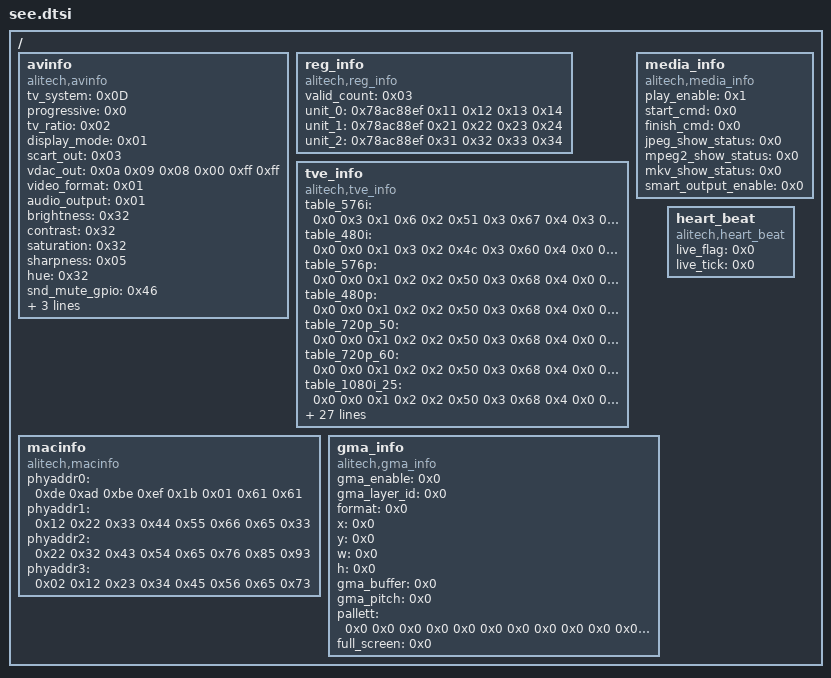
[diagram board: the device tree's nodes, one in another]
/*
 * ALi platform DTS
 * Copyright(C) 2014 ALi Corporation. All rights reserved.
 *
 * This program is free software; you can redistribute it and/or modify
 * it under the terms of the GNU General Public License version 2 as
 * published by the Free Software Foundation.
 *
 * This program is distributed in the hope that it will be useful,
 * but WITHOUT ANY WARRANTY; without even the implied warranty of
 * MERCHANTABILITY or FITNESS FOR A PARTICULAR PURPOSE.  See the
 * GNU General Public License for more details.
 */

/{
		#size-cells = <2>;
		avinfo{
			compatible="alitech,avinfo";
			/*eric.cai debug*/
			/* tv_system = /bits/ 8 <0x0D>; */
			tv_system = /bits/ 8 <0x0D>; 
			progressive = /bits/ 8 <0x0>;
			tv_ratio= /bits/ 8 <0x02>;
			display_mode = /bits/ 8 <0x01>;
			scart_out = /bits/ 8 <0x03>;
			vdac_out = /bits/ 8 <0x0a 0x09 0x08 0x00 0xff 0xff>;
			video_format = /bits/ 8 <0x01>;
			audio_output = /bits/ 8 <0x01>;
			brightness = /bits/ 8 <0x32>;
			contrast = /bits/ 8 <0x32>;
			saturation = /bits/ 8 <0x32>;
			sharpness = /bits/ 8 <0x05>;
			hue = /bits/ 8 <0x32>;
			snd_mute_gpio = /bits/ 8 <0x46>;
			snd_mute_polar = /bits/ 8 <0x0>;
			hdcp_disable = /bits/ 8 <0x01>;
			resv = /bits/ 8 <0x00 0x01 0x02 0x03 0x04 0x05 0x06>;
		};
		reg_info{
					compatible="alitech,reg_info";
					valid_count = <0x03>;
					unit_0 = <0x78ac88ef 0x11 0x12 0x13  0x14>; /* magic addr bits_offset bits_size bits_value */
					unit_1 = <0x78ac88ef 0x21 0x22 0x23  0x24>;
					unit_2 = <0x78ac88ef 0x31 0x32 0x33  0x34>;
		};

		tve_info{
		compatible="alitech,tve_info";
		table_576i = /* field_index  field_value */
								< 0x0 0x3    0x1 0x6   0x2 0x51   0x3 0x67   0x4 0x3   0x5 0x2   0x6 0x0    0x7 0x1   0x8 0x0    0x9  0x1 
									0xa 0x0    0xb 0x0   0xc 0x0    0xd 0x1    0xe 0x1   0xf 0x2   0x10 0x2   0x11 0x2  0x12 0x52  0x13 0x50
									0x14 0xb   0x15 0x0  0x16 0x7   0x17 0x3   0x18 0x0  0x19 0x0  0x1a  0x0  0x1b 0x47 0x1c 0x47  0x1d 0x47 
									0x1e 0x1   0x1f 0x1  0x20 0x0   0x21 0x0   0x22 0x0  0x23 0x12a 0x24 0x64 0x25 0xd0 0x26 0x205 0x27  0x198 
									0x28 0x1   0x29 0x1  0x2a 0x96  0x2b 0x6a  0x2c 0x55 0x2d 0x74  0x2e 0x0  0x2f 0x0  0x30 0x61e8 0x31 0x0 
									0x32 0x4   0x33 0x1  0x34 0x6   0x35 0xd   0x36 0x0  0x37 0x0   0x38 0x0  0x39 0x0  0x3a 0x0    0x3b 0x0 
									0x3c 0x0   0x3d 0x0  0x3e 0x0   0x3f 0x0   0x40 0x0  0x41 0x1   0x42 0x4  0x43 0x0  0x44 0x0    0x45 0x60 
									0x46 0x0   0x47 0x0  0x48 0x1f  0x49 0x2   0x4a 0x0  0x0  0x0   0x0  0x0  0x0 0x0   0x0  0x0    0x0  0x0 
									0x0  0x0   0x0  0x0  0x0  0x0   0x0  0x0   0x0  0x0  0x0  0x0   0x0  0x0  0x0 0x0   0x0  0x0    0x0  0x0 
									0x0  0x0   0x0  0x0  0x0  0x0   0x0  0x0   0x0  0x0  0x0  0x0   0x0  0x0  0x0 0x0   0x0  0x0    0x0  0x0 >;
		table_480i = /* field_index  field_value */
								< 0x0     0x0     0x1     0x3     0x2     0x4c    0x3     0x60    0x4     0x0     0x5     0x5     0x6   0x0     0x7     0x1     0x8     0x0     0x9     0x0 
0xa     0x0     0xb     0x0     0xc     0x1     0xd     0x1     0xe     0x1     0xf     0x3     0x10    0x1     0x11    0x1     0x12    0x4c    0x13    0x52 
0x14    0xb     0x15    0x0     0x16    0x7     0x17    0x3     0x18    0x0     0x19    0x0     0x1a    0x0     0x1b    0x47    0x1c    0x47    0x1d    0x47 
0x1e    0x1     0x1f    0x1     0x20    0x1     0x21    0x1     0x22    0xa8    0x23    0x12a   0x24    0x64    0x25    0xd0    0x26    0x205   0x27    0x198 
0x28    0x0     0x29    0x1     0x2a    0xd4    0x2b    0x0     0x2c    0x55    0x2d    0x74    0x2e    0x0     0x2f    0x0     0x30    0x3400  0x31    0x0 
0x32    0x4     0x33    0x1     0x34    0x6     0x35    0xd     0x36    0x0     0x37    0x0     0x38    0x0     0x39    0x0     0x3a    0x0     0x3b    0x0 
0x3c    0x0     0x3d    0x0     0x3e    0x0     0x3f    0x0     0x40    0x0     0x41    0x1     0x42    0x7     0x43    0x1     0x44    0x1     0x45    0x60 
0x46    0x0     0x47    0x0     0x48    0x1f    0x49    0x2     0x4a    0x0     0x0     0x0     0x0     0x0     0x0     0x0     0x0     0x0     0x0     0x0 
0x0     0x0     0x0     0x0     0x0     0x0     0x0     0x0     0x0     0x0     0x0     0x0     0x0     0x0     0x0     0x0     0x0     0x0     0x0     0x0 
0x0     0x0     0x0     0x0     0x0     0x0     0x0     0x0     0x0     0x0     0x0     0x0     0x0     0x0     0x0     0x0     0x0     0x0     0x0     0x0  >;
		table_576p = /* field_index  field_value */
								< 0x0     0x0     0x1     0x2     0x2     0x50    0x3     0x68    0x4     0x0     0x5     0x4     0x6     0x0     0x7     0x1     0x8     0x0     0x9     0x0 
0xa     0x0     0xb     0x0     0xc     0x0     0xd     0x1     0xe     0x1     0xf     0x1     0x10    0x1     0x11    0x1     0x12    0x52    0x13    0x52 
0x14    0xa     0x15    0x0     0x16    0x7     0x17    0x3     0x18    0x0     0x19    0x0     0x1a    0x0     0x1b    0x49    0x1c    0x49    0x1d    0x49 
0x1e    0x1     0x1f    0x1     0x20    0x0     0x21    0x0     0x22    0x0     0x23    0x12a   0x24    0x64    0x25    0xd0    0x26    0x205   0x27    0x198 
0x28    0x0     0x29    0x0     0x2a    0xd4    0x2b    0x0     0x2c    0x0     0x2d    0x0     0x2e    0x0     0x2f    0x0     0x30    0x0     0x31    0x0 
0x32    0x4     0x33    0x1     0x34    0x6     0x35    0xd     0x36    0x0     0x37    0x0     0x38    0x0     0x39    0x0     0x3a    0x0     0x3b    0x0 
0x3c    0x0     0x3d    0x0     0x3e    0x0     0x3f    0x0     0x40    0x0     0x41    0x1     0x42    0xe     0x43    0x0     0x44    0x0     0x45    0x60 
0x46    0x0     0x47    0x0     0x48    0x1f    0x49    0x2     0x4a    0x0     0x0     0x0     0x0     0x0     0x0     0x0     0x0     0x0     0x0     0x0 
0x0     0x0     0x0     0x0     0x0     0x0     0x0     0x0     0x0     0x0     0x0     0x0     0x0     0x0     0x0     0x0     0x0     0x0     0x0     0x0 
0x0     0x0     0x0     0x0     0x0     0x0     0x0     0x0     0x0     0x0     0x0     0x0     0x0     0x0     0x0     0x0     0x0     0x0     0x0     0x0  >;
		table_480p = /* field_index  field_value */
								< 0x0     0x0     0x1     0x2     0x2     0x50    0x3     0x68    0x4     0x0     0x5     0x4     0x6     0x0     0x7     0x1     0x8     0x0     0x9     0x0 
0xa     0x0     0xb     0x0     0xc     0x0     0xd     0x1     0xe     0x1     0xf     0x1     0x10    0x1     0x11    0x1     0x12    0x52    0x13    0x52 
0x14    0xa     0x15    0x0     0x16    0x7     0x17    0x3     0x18    0x0     0x19    0x0     0x1a    0x0     0x1b    0x49    0x1c    0x49    0x1d    0x49 
0x1e    0x1     0x1f    0x1     0x20    0x0     0x21    0x0     0x22    0x0     0x23    0x12a   0x24    0x64    0x25    0xd0    0x26    0x205   0x27    0x198 
0x28    0x0     0x29    0x0     0x2a    0xd4    0x2b    0x0     0x2c    0x0     0x2d    0x0     0x2e    0x0     0x2f    0x0     0x30    0x0     0x31    0x0 
0x32    0x4     0x33    0x1     0x34    0x6     0x35    0xd     0x36    0x0     0x37    0x0     0x38    0x0     0x39    0x0     0x3a    0x0     0x3b    0x0 
0x3c    0x0     0x3d    0x0     0x3e    0x0     0x3f    0x0     0x40    0x0     0x41    0x1     0x42    0xe     0x43    0x0     0x44    0x0     0x45    0x60 
0x46    0x0     0x47    0x0     0x48    0x1f    0x49    0x2     0x4a    0x0     0x0     0x0     0x0     0x0     0x0     0x0     0x0     0x0     0x0     0x0 
0x0     0x0     0x0     0x0     0x0     0x0     0x0     0x0     0x0     0x0     0x0     0x0     0x0     0x0     0x0     0x0     0x0     0x0     0x0     0x0 
0x0     0x0     0x0     0x0     0x0     0x0     0x0     0x0     0x0     0x0     0x0     0x0     0x0     0x0     0x0     0x0     0x0     0x0     0x0     0x0 >;
		table_720p_50 = /* field_index  field_value */
								<0x0     0x0     0x1     0x2     0x2     0x50    0x3     0x68    0x4     0x0     0x5     0x4     0x6     0x0     0x7     0x1     0x8     0x0     0x9     0x0 
0xa     0x0     0xb     0x0     0xc     0x0     0xd     0x1     0xe     0x1     0xf     0x6     0x10    0x5     0x11    0x5     0x12    0x52    0x13    0x52 
0x14    0x0     0x15    0x0     0x16    0x0     0x17    0x3     0x18    0x0     0x19    0x0     0x1a    0x0     0x1b    0x49    0x1c    0x49    0x1d    0x49 
0x1e    0x1     0x1f    0x1     0x20    0x0     0x21    0x0     0x22    0x0     0x23    0x12a   0x24    0x64    0x25    0xd0    0x26    0x21d   0x27    0x1cb 
0x28    0x0     0x29    0x0     0x2a    0xd4    0x2b    0x0     0x2c    0x0     0x2d    0x0     0x2e    0x0     0x2f    0x0     0x30    0x0     0x31    0x0 
0x32    0x4     0x33    0x1     0x34    0x6     0x35    0xd     0x36    0x0     0x37    0x0     0x38    0x0     0x39    0x0     0x3a    0x0     0x3b    0x0 
0x3c    0x0     0x3d    0x0     0x3e    0x0     0x3f    0x0     0x40    0x0     0x41    0x1     0x42    0x6     0x43    0x0     0x44    0x0     0x45    0x60 
0x46    0x0     0x47    0x0     0x48    0x1f    0x49    0x2     0x4a    0x0     0x0     0x0     0x0     0x0     0x0     0x0     0x0     0x0     0x0     0x0 
0x0     0x0     0x0     0x0     0x0     0x0     0x0     0x0     0x0     0x0     0x0     0x0     0x0     0x0     0x0     0x0     0x0     0x0     0x0     0x0 
0x0     0x0     0x0     0x0     0x0     0x0     0x0     0x0     0x0     0x0     0x0     0x0     0x0     0x0     0x0     0x0     0x0     0x0     0x0     0x0 >;
		table_720p_60 = /* field_index  field_value */
								< 0x0     0x0     0x1     0x2     0x2     0x50    0x3     0x68    0x4     0x0     0x5     0x4     0x6     0x0     0x7     0x1     0x8     0x0     0x9     0x0 
0xa     0x0     0xb     0x0     0xc     0x0     0xd     0x1     0xe     0x1     0xf     0x7     0x10    0x6     0x11    0x6     0x12    0x52    0x13    0x52 
0x14    0x0     0x15    0x0     0x16    0x5     0x17    0x3     0x18    0x0     0x19    0x0     0x1a    0x0     0x1b    0x49    0x1c    0x49    0x1d    0x49 
0x1e    0x1     0x1f    0x1     0x20    0x0     0x21    0x0     0x22    0x0     0x23    0x12a   0x24    0x64    0x25    0xd0    0x26    0x21d   0x27    0x1cb 
0x28    0x0     0x29    0x0     0x2a    0xd4    0x2b    0x0     0x2c    0x0     0x2d    0x0     0x2e    0x0     0x2f    0x0     0x30    0x0     0x31    0x0 
0x32    0x4     0x33    0x1     0x34    0x6     0x35    0xf     0x36    0x0     0x37    0x0     0x38    0x0     0x39    0x0     0x3a    0x0     0x3b    0x0 
0x3c    0x0     0x3d    0x0     0x3e    0x0     0x3f    0x0     0x40    0x0     0x41    0x1     0x42    0x6     0x43    0x0     0x44    0x0     0x45    0x60 
0x46    0x0     0x47    0x0     0x48    0x1f    0x49    0x2     0x4a    0x0     0x0     0x0     0x0     0x0     0x0     0x0     0x0     0x0     0x0     0x0 
0x0     0x0     0x0     0x0     0x0     0x0     0x0     0x0     0x0     0x0     0x0     0x0     0x0     0x0     0x0     0x0     0x0     0x0     0x0     0x0 
0x0     0x0     0x0     0x0     0x0     0x0     0x0     0x0     0x0     0x0     0x0     0x0     0x0     0x0     0x0     0x0     0x0     0x0     0x0     0x0 >;
		table_1080i_25 = /* field_index  field_value */
								< 0x0     0x0     0x1     0x2     0x2     0x50    0x3     0x68    0x4     0x0     0x5     0x4     0x6     0x0     0x7     0x1     0x8     0x0     0x9     0x0 
0xa     0x0     0xb     0x0     0xc     0x0     0xd     0x1     0xe     0x1     0xf     0x6     0x10    0x5     0x11    0x5     0x12    0x52    0x13    0x52 
0x14    0x0     0x15    0x0     0x16    0x5     0x17    0x3     0x18    0x0     0x19    0x0     0x1a    0x0     0x1b    0x49    0x1c    0x49    0x1d    0x49 
0x1e    0x1     0x1f    0x1     0x20    0x0     0x21    0x0     0x22    0x0     0x23    0x12a   0x24    0x64    0x25    0xd0    0x26    0x21d   0x27    0x1cb 
0x28    0x0     0x29    0x0     0x2a    0xd4    0x2b    0x0     0x2c    0x0     0x2d    0x0     0x2e    0x0     0x2f    0x0     0x30    0x0     0x31    0x0 
0x32    0x4     0x33    0x1     0x34    0x6     0x35    0xd     0x36    0x0     0x37    0x0     0x38    0x0     0x39    0x0     0x3a    0x0     0x3b    0x0 
0x3c    0x0     0x3d    0x0     0x3e    0x0     0x3f    0x0     0x40    0x0     0x41    0x1     0x42    0x6     0x43    0x0     0x44    0x0     0x45    0x60 
0x46    0x0     0x47    0x0     0x48    0x1f    0x49    0x2     0x4a    0x0     0x0     0x0     0x0     0x0     0x0     0x0     0x0     0x0     0x0     0x0 
0x0     0x0     0x0     0x0     0x0     0x0     0x0     0x0     0x0     0x0     0x0     0x0     0x0     0x0     0x0     0x0     0x0     0x0     0x0     0x0 
0x0     0x0     0x0     0x0     0x0     0x0     0x0     0x0     0x0     0x0     0x0     0x0     0x0     0x0     0x0     0x0     0x0     0x0     0x0     0x0 >;
		table_1080i_30 = /* field_index  field_value */
								< 0x0     0x0     0x1     0x2     0x2     0x50    0x3     0x68    0x4     0x0     0x5     0x4     0x6     0x0     0x7     0x1     0x8     0x0     0x9     0x0 
0xa     0x0     0xb     0x0     0xc     0x0     0xd     0x1     0xe     0x1     0xf     0x6     0x10    0x5     0x11    0x5     0x12    0x52    0x13    0x51 
0x14    0x0     0x15    0x0     0x16    0x5     0x17    0x3     0x18    0x0     0x19    0x0     0x1a    0x0     0x1b    0x49    0x1c    0x49    0x1d    0x49 
0x1e    0x1     0x1f    0x1     0x20    0x0     0x21    0x0     0x22    0x0     0x23    0x12a   0x24    0x64    0x25    0xd0    0x26    0x21d   0x27    0x1cb 
0x28    0x0     0x29    0x0     0x2a    0xd4    0x2b    0x0     0x2c    0x0     0x2d    0x0     0x2e    0x0     0x2f    0x0     0x30    0x0     0x31    0x0 
0x32    0x4     0x33    0x1     0x34    0x6     0x35    0xd     0x36    0x0     0x37    0x0     0x38    0x0     0x39    0x0     0x3a    0x0     0x3b    0x0 
0x3c    0x0     0x3d    0x0     0x3e    0x0     0x3f    0x0     0x40    0x0     0x41    0x1     0x42    0x6     0x43    0x0     0x44    0x0     0x45    0x60 
0x46    0x0     0x47    0x0     0x48    0x1f    0x49    0x2     0x4a    0x0     0x0     0x0     0x0     0x0     0x0     0x0     0x0     0x0     0x0     0x0 
0x0     0x0     0x0     0x0     0x0     0x0     0x0     0x0     0x0     0x0     0x0     0x0     0x0     0x0     0x0     0x0     0x0     0x0     0x0     0x0 
0x0     0x0     0x0     0x0     0x0     0x0     0x0     0x0     0x0     0x0     0x0     0x0     0x0     0x0     0x0     0x0     0x0     0x0     0x0     0x0 >;
		table_1080p_24 = /* field_index  field_value */
								< 0x0     0x0     0x1     0x2     0x2     0x50    0x3     0x68    0x4     0x0     0x5     0x4     0x6     0x0     0x7     0x1     0x8     0x0     0x9     0x0 
0xa     0x0     0xb     0x0     0xc     0x0     0xd     0x1     0xe     0x1     0xf     0x6     0x10    0x5     0x11    0x5     0x12    0x52    0x13    0x52 
0x14    0x0     0x15    0x0     0x16    0x5     0x17    0x3     0x18    0x0     0x19    0x0     0x1a    0x0     0x1b    0x49    0x1c    0x49    0x1d    0x49 
0x1e    0x1     0x1f    0x1     0x20    0x0     0x21    0x0     0x22    0x0     0x23    0x12a   0x24    0x64    0x25    0xd0    0x26    0x21d   0x27    0x1cb 
0x28    0x0     0x29    0x0     0x2a    0xd4    0x2b    0x0     0x2c    0x0     0x2d    0x0     0x2e    0x0     0x2f    0x0     0x30    0x0     0x31    0x0 
0x32    0x4     0x33    0x1     0x34    0x6     0x35    0xd     0x36    0x0     0x37    0x0     0x38    0x0     0x39    0x0     0x3a    0x0     0x3b    0x0 
0x3c    0x0     0x3d    0x0     0x3e    0x0     0x3f    0x0     0x40    0x0     0x41    0x1     0x42    0x6     0x43    0x0     0x44    0x0     0x45    0x60 
0x46    0x0     0x47    0x0     0x48    0x1f    0x49    0x2     0x4a    0x0     0x0     0x0     0x0     0x0     0x0     0x0     0x0     0x0     0x0     0x0 
0x0     0x0     0x0     0x0     0x0     0x0     0x0     0x0     0x0     0x0     0x0     0x0     0x0     0x0     0x0     0x0     0x0     0x0     0x0     0x0 
0x0     0x0     0x0     0x0     0x0     0x0     0x0     0x0     0x0     0x0     0x0     0x0     0x0     0x0     0x0     0x0     0x0     0x0     0x0     0x0 >;
		table_1080p_25 = /* field_index  field_value */
								< 0x0     0x0     0x1     0x2     0x2     0x50    0x3     0x68    0x4     0x0     0x5     0x4     0x6     0x0     0x7     0x1     0x8     0x0     0x9     0x0 
0xa     0x0     0xb     0x0     0xc     0x0     0xd     0x1     0xe     0x1     0xf     0x6     0x10    0x5     0x11    0x5     0x12    0x52    0x13    0x52 
0x14    0x0     0x15    0x0     0x16    0x5     0x17    0x3     0x18    0x0     0x19    0x0     0x1a    0x0     0x1b    0x49    0x1c    0x49    0x1d    0x49 
0x1e    0x1     0x1f    0x1     0x20    0x0     0x21    0x0     0x22    0x0     0x23    0x12a   0x24    0x64    0x25    0xd0    0x26    0x21d   0x27    0x1cb 
0x28    0x0     0x29    0x0     0x2a    0xd4    0x2b    0x0     0x2c    0x0     0x2d    0x0     0x2e    0x0     0x2f    0x0     0x30    0x0     0x31    0x0 
0x32    0x4     0x33    0x1     0x34    0x6     0x35    0xd     0x36    0x0     0x37    0x0     0x38    0x0     0x39    0x0     0x3a    0x0     0x3b    0x0 
0x3c    0x0     0x3d    0x0     0x3e    0x0     0x3f    0x0     0x40    0x0     0x41    0x1     0x42    0x6     0x43    0x0     0x44    0x0     0x45    0x60 
0x46    0x0     0x47    0x0     0x48    0x1f    0x49    0x2     0x4a    0x0     0x0     0x0     0x0     0x0     0x0     0x0     0x0     0x0     0x0     0x0 
0x0     0x0     0x0     0x0     0x0     0x0     0x0     0x0     0x0     0x0     0x0     0x0     0x0     0x0     0x0     0x0     0x0     0x0     0x0     0x0 
0x0     0x0     0x0     0x0     0x0     0x0     0x0     0x0     0x0     0x0     0x0     0x0     0x0     0x0     0x0     0x0     0x0     0x0     0x0     0x0 
 >;
		table_1080p_30 = /* field_index  field_value */
								< 0x0     0x0     0x1     0x2     0x2     0x50    0x3     0x68    0x4     0x0     0x5     0x4     0x6     0x0     0x7     0x1     0x8     0x0     0x9     0x0 
0xa     0x0     0xb     0x0     0xc     0x0     0xd     0x1     0xe     0x1     0xf     0x5     0x10    0x4     0x11    0x4     0x12    0x52    0x13    0x52 
0x14    0x0     0x15    0x0     0x16    0x5     0x17    0x3     0x18    0x0     0x19 0x0        0x1a    0x0     0x1b    0x49    0x1c    0x49    0x1d    0x49 
0x1e    0x1     0x1f    0x1     0x20    0x0     0x21    0x0     0x22    0x0     0x23    0x12a   0x24    0x64    0x25    0xd0    0x26    0x21d   0x27    0x1cb 
0x28    0x0     0x29    0x0     0x2a    0xd4    0x2b    0x0     0x2c    0x0     0x2d    0x0     0x2e    0x0     0x2f    0x0     0x30    0x0     0x31    0x0 
0x32    0x4     0x33    0x1     0x34    0x6     0x35    0xd     0x36    0x0     0x37    0x0     0x38    0x0     0x39    0x0     0x3a    0x0     0x3b    0x0 
0x3c    0x0     0x3d    0x0     0x3e    0x0     0x3f    0x0     0x40    0x0     0x41    0x1     0x42    0x6     0x43    0x0     0x44    0x0     0x45    0x60 
0x46    0x0     0x47    0x0     0x48    0x1f    0x49    0x2     0x4a    0x0     0x0     0x0     0x0     0x0     0x0     0x0     0x0     0x0     0x0     0x0 
0x0     0x0     0x0     0x0     0x0     0x0     0x0     0x0     0x0     0x0     0x0     0x0     0x0     0x0     0x0     0x0     0x0     0x0     0x0     0x0 
0x0     0x0     0x0     0x0     0x0     0x0     0x0     0x0     0x0     0x0     0x0     0x0     0x0     0x0     0x0     0x0     0x0     0x0     0x0     0x0  >;
		table_1152i_25 = /* field_index  field_value */
								< 0x0     0x0     0x1     0x2     0x2     0x50    0x3     0x68    0x4     0x0     0x5     0x4     0x6     0x0     0x7     0x1     0x8     0x0     0x9     0x0 
0xa     0x0     0xb     0x0     0xc     0x0     0xd     0x1     0xe     0x1     0xf     0x6     0x10    0x5     0x11    0x5     0x12    0x52    0x13    0x4d 
0x14    0x0     0x15    0x0     0x16    0x5     0x17    0x3     0x18    0x0     0x19    0x0     0x1a    0x0     0x1b    0x49    0x1c    0x49    0x1d    0x49 
0x1e    0x1     0x1f    0x1     0x20    0x0     0x21    0x0     0x22    0x0     0x23    0x12a   0x24    0x64    0x25    0xd0    0x26    0x21d   0x27    0x1cb 
0x28    0x0     0x29    0x0     0x2a    0xd4    0x2b    0x0     0x2c    0x0     0x2d    0x0     0x2e    0x0     0x2f    0x0     0x30    0x0     0x31    0x0 
0x32    0x4     0x33    0x1     0x34    0x6     0x35    0xd     0x36    0x0     0x37    0x0     0x38    0x0     0x39    0x0     0x3a    0x0     0x3b    0x0 
0x3c    0x0     0x3d    0x0     0x3e    0x0     0x3f    0x0     0x40    0x0     0x41    0x1     0x42    0x6     0x43    0x0     0x44    0x0     0x45    0x60 
0x46    0x0     0x47    0x0     0x48    0x1f    0x49    0x2     0x4a    0x0     0x0     0x0     0x0     0x0     0x0     0x0     0x0     0x0     0x0     0x0 
0x0     0x0     0x0     0x0     0x0     0x0     0x0     0x0     0x0     0x0     0x0     0x0     0x0     0x0     0x0     0x0     0x0     0x0     0x0     0x0 
0x0     0x0     0x0     0x0     0x0     0x0     0x0     0x0     0x0     0x0     0x0     0x0     0x0     0x0     0x0     0x0     0x0     0x0     0x0     0x0  >;
		table_1080IASS = /* field_index  field_value */
								< 0x0     0x0     0x1     0x2     0x2     0x50    0x3     0x68    0x4     0x0     0x5     0x4     0x6     0x0     0x7     0x1     0x8     0x0     0x9     0x0 
0xa     0x0     0xb     0x0     0xc     0x0     0xd     0x1     0xe     0x1     0xf     0x6     0x10    0x5     0x11    0x5     0x12    0x52    0x13    0x4d 
0x14    0x0     0x15    0x0     0x16    0x5     0x17    0x3     0x18    0x0     0x19    0x0     0x1a    0x0     0x1b    0x49    0x1c    0x49    0x1d    0x49 
0x1e    0x1     0x1f    0x1     0x20    0x0     0x21    0x0     0x22    0x0     0x23    0x12a   0x24    0x64    0x25    0xd0    0x26    0x21d   0x27    0x1cb 
0x28    0x0     0x29    0x0     0x2a    0xd4    0x2b    0x0     0x2c    0x0     0x2d    0x0     0x2e    0x0     0x2f    0x0     0x30    0x0     0x31    0x0 
0x32    0x4     0x33    0x1     0x34    0x6     0x35    0xd     0x36    0x0     0x37    0x0     0x38    0x0     0x39    0x0     0x3a    0x0     0x3b    0x0 
0x3c    0x0     0x3d    0x0     0x3e    0x0     0x3f    0x0     0x40    0x0     0x41    0x1     0x42    0x6     0x43    0x0     0x44    0x0     0x45    0x60 
0x46    0x0     0x47    0x0     0x48    0x1f    0x49    0x2     0x4a    0x0     0x0     0x0     0x0     0x0     0x0     0x0     0x0     0x0     0x0     0x0 
0x0     0x0     0x0     0x0     0x0     0x0     0x0     0x0     0x0     0x0     0x0     0x0     0x0     0x0     0x0     0x0     0x0     0x0     0x0     0x0 
0x0     0x0     0x0     0x0     0x0     0x0     0x0     0x0     0x0     0x0     0x0     0x0     0x0     0x0     0x0     0x0     0x0     0x0     0x0     0x0 >;
		table_1080p_50 = /* field_index  field_value */
								< 
0x0     0x0     0x1     0x2     0x2     0x50    0x3     0x68    0x4     0x0     0x5     0x4     0x6     0x0     0x7     0x1     0x8     0x0     0x9     0x0 
0xa     0x0     0xb     0x0     0xc     0x0     0xd     0x1     0xe     0x1     0xf     0x6     0x10    0x6     0x11    0x6     0x12    0x52    0x13    0x51 
0x14    0x0     0x15    0x0     0x16    0x0     0x17    0x3     0x18    0x0     0x19    0x0     0x1a    0x0     0x1b    0x49    0x1c    0x49    0x1d    0x49 
0x1e    0x1     0x1f    0x1     0x20    0x0     0x21    0x0     0x22    0x0     0x23    0x12a   0x24    0x64    0x25    0xd0    0x26    0x21d   0x27    0x1cb 
0x28    0x0     0x29    0x0     0x2a    0xd4    0x2b    0x0     0x2c    0x0     0x2d    0x0     0x2e    0x0     0x2f    0x0     0x30    0x0     0x31    0x0 
0x32    0x2     0x33    0x2     0x34    0x0     0x35    0xd     0x36    0x0     0x37    0x0     0x38    0x0     0x39    0x0     0x3a    0x0     0x3b    0x0 
0x3c    0x0     0x3d    0x0     0x3e    0x0     0x3f    0x0     0x40    0x0     0x41    0x1     0x42    0x6     0x43    0x1     0x44    0x0     0x45    0x60 
0x46    0x0     0x47    0x0     0x48    0x1f    0x49    0x2     0x4a    0x0     0x0     0x0     0x0     0x0     0x0     0x0     0x0     0x0     0x0     0x0 
0x0     0x0     0x0     0x0     0x0     0x0     0x0     0x0     0x0     0x0     0x0     0x0     0x0     0x0     0x0     0x0     0x0     0x0     0x0     0x0 
0x0     0x0     0x0     0x0     0x0     0x0     0x0     0x0     0x0     0x0     0x0     0x0     0x0     0x0     0x0     0x0     0x0     0x0     0x0     0x0  >;
		table_1080p_60 = /* field_index  field_value */
								< 
0x0     0x0     0x1     0x2     0x2     0x50    0x3     0x68    0x4     0x0     0x5     0x4     0x6     0x0     0x7     0x1     0x8     0x0     0x9     0x0 
0xa     0x0     0xb     0x0     0xc     0x0     0xd     0x1     0xe     0x1     0xf     0x4     0x10    0x5     0x11    0x5     0x12    0x52    0x13    0x51 
0x14    0x0     0x15    0x0     0x16    0x0     0x17    0x3     0x18    0x0     0x19    0x0     0x1a    0x0     0x1b    0x49    0x1c    0x49    0x1d    0x49 
0x1e    0x1     0x1f    0x1     0x20    0x0     0x21    0x0     0x22    0x0     0x23    0x12a   0x24    0x64    0x25    0xd0    0x26    0x21d   0x27    0x1cb 
0x28    0x0     0x29    0x0     0x2a    0xd4    0x2b    0x0     0x2c    0x0     0x2d    0x0     0x2e    0x0     0x2f    0x0     0x30    0x0     0x31    0x0 
0x32    0x2     0x33    0x2     0x34    0xb     0x35    0xb     0x36    0x0     0x37    0x0     0x38    0x0     0x39    0x0     0x3a    0x0     0x3b    0x0 
0x3c    0x0     0x3d    0x0     0x3e    0x0     0x3f    0x0     0x40    0x0     0x41    0x1     0x42    0x6     0x43    0x1     0x44    0x0     0x45    0x60 
0x46    0x0     0x47    0x0     0x48    0x1f    0x49    0x2     0x4a    0x0     0x0     0x0     0x0     0x0     0x0     0x0     0x0     0x0     0x0     0x0 
0x0     0x0     0x0     0x0     0x0     0x0     0x0     0x0     0x0     0x0     0x0     0x0     0x0     0x0     0x0     0x0     0x0     0x0     0x0     0x0 
0x0     0x0     0x0     0x0     0x0     0x0     0x0     0x0     0x0     0x0     0x0     0x0     0x0     0x0     0x0     0x0     0x0     0x0     0x0     0x0  >;
		tve_adjust_table =
				"table_576i",
       	"table_480i",
        "table_576p",
        "table_480p",
        "table_720p_50",
        "table_720p_60",
       	"table_1080i_25",
        "table_1080i_30",
        "table_1080p_24",
        "table_1080p_25",
        "table_1080p_30",
        "table_1152i_25",
        "table_1080IASS",
        "table_1080p_50",
        "table_1080p_60";

		sd_tve_adj_table_info = 
												 < 0x0   0x1   0x1   
												   0x0   0x0   0x1   
												   0x1   0x1   0x0   
												   0x1   0x0   0x0   
												   0x2   0x1   0x4   
												   0x2   0x0   0x4   
												   0x3   0x1   0x3   
												   0x3   0x0   0x3   
												   0x4   0x1   0x1   
												   0x4   0x0   0x1   
												   0x5   0x1   0x1   
												   0x5   0x0   0x0   
												   0x6   0x1   0x85  
												   0x6   0x0   0x85  
												   0x7   0x1   0x55  
												   0x7   0x0   0x55  
												   0x8   0x1   0x52  
												   0x8   0x0   0x4d  
												   0x9   0x1   0x6   
												   0x9   0x0   0x6   
												   0xa   0x1   0x280        
												   0xa   0x0   0x4a0        
												   0xb   0x1   0x102        
												   0xb   0x0   0x102        
												   0x0   0x0   0x0   
												   0x0   0x0   0x0   
												   0x0   0x0   0x0   
												   0x0   0x0   0x0   
												   0x0   0x0   0x0   
												   0x0   0x0   0x0   
												   0x0   0x0   0x0   
												   0x0   0x0   0x0   
												   0x0   0x0   0x0   
												   0x0   0x0   0x0   
												   0x0   0x0   0x0   
												   0x0   0x0   0x0   
												   0x0   0x0   0x0   
												   0x0   0x0   0x0   
												   0x0   0x0   0x0   
												   0x0   0x0   0x0   
												   0x0   0x0   0x0   
												   0x0   0x0   0x0   
												   0x0   0x0   0x0   
												   0x0   0x0   0x0   
												   0x0   0x0   0x0   
												   0x0   0x0   0x0   
												   0x0   0x0   0x0   
												   0x0   0x0   0x0   
												   0x0   0x0   0x0   
												   0x0   0x0   0x0   
												   0x0   0x0   0x0   
												   0x0   0x0   0x0   
												   0x0   0x0   0x0   
												   0x0   0x0   0x0   
												   0x0   0x0   0x0   
												   0x0   0x0   0x0   
												   0x0   0x0   0x0   
												   0x0   0x0   0x0   
												   0x0   0x0   0x0   
												   0x0   0x0   0x0   
												   0x0   0x0   0x0   
												   0x0   0x0   0x0   
												   0x0   0x0   0x0   
												   0x0   0x0   0x0   
												   0x0   0x0   0x0   
												   0x0   0x0   0x0   
												   0x0   0x0   0x0   
												   0x0   0x0   0x0   
												   0x0   0x0   0x0   
												   0x0   0x0   0x0   
												   0x0   0x0   0x0   
												   0x0   0x0   0x0   
												   0x0   0x0   0x0   
												   0x0   0x0   0x0   
												   0x0   0x0   0x0   
												   0x0   0x0   0x0   
												   0x0   0x0   0x0   
												   0x0   0x0   0x0   
												   0x0   0x0   0x0   
												   0x0   0x0   0x0   
												   0x0   0x0   0x0   
												   0x0   0x0   0x0   
												   0x0   0x0   0x0   
												   0x0   0x0   0x0   
												   0x0   0x0   0x0   
												   0x0   0x0   0x0   
												   0x0   0x0   0x0   
												   0x0   0x0   0x0   
												   0x0   0x0   0x0   
												   0x0   0x0   0x0   
												   0x0   0x0   0x0   
												   0x0   0x0   0x0   
												   0x0   0x0   0x0   
												   0x0   0x0   0x0   
												   0x0   0x0   0x0   
												   0x0   0x0   0x0   
												   0x0   0x0   0x0   
												   0x0   0x0   0x0   
												   0x0   0x0   0x0   
												   0x0   0x0   0x0>;

		sd_tve_adv_adj_table_info =
												 < 0x0   0x1   0x0   
												   0x0   0x0   0x1   
												   0x1   0x1   0x53  
												   0x1   0x0   0x4f  
												   0x2   0x1   0x51  
												   0x2   0x0   0x51  
												   0x3   0x1   0x0   
												   0x3   0x0   0x9   
												   0x4   0x1   0x0   
												   0x4   0x0   0x4   
												   0x5   0x1   0x8f  
												   0x5   0x0   0x92  
												   0x6   0x1   0x8e  
												   0x6   0x0   0x91  
												   0x7   0x1   0x8e  
												   0x7   0x0   0x91  
												   0x8   0x1   0x0   
												   0x8   0x0   0x2b  
												   0x9   0x1   0x0   
												   0x9   0x0   0x5   
												   0xa   0x1   0x0   
												   0xa   0x0   0x0   
												   0xb   0x1   0x0   
												   0xb   0x0   0x0   
												   0xc   0x1   0x0   
												   0xc   0x0   0x0   
												   0x0   0x0   0x0   
												   0x0   0x0   0x0   
												   0x0   0x0   0x0   
												   0x0   0x0   0x0   
												   0x0   0x0   0x0   
												   0x0   0x0   0x0   
												   0x0   0x0   0x0   
												   0x0   0x0   0x0   
												   0x0   0x0   0x0   
												   0x0   0x0   0x0   
												   0x0   0x0   0x0   
												   0x0   0x0   0x0   
												   0x0   0x0   0x0   
												   0x0   0x0   0x0   
												   0x0   0x0   0x0   
												   0x0   0x0   0x0   
												   0x0   0x0   0x0   
												   0x0   0x0   0x0   
												   0x0   0x0   0x0   
												   0x0   0x0   0x0   
												   0x0   0x0   0x0   
												   0x0   0x0   0x0   
												   0x0   0x0   0x0   
												   0x0   0x0   0x0   
												   0x0   0x0   0x0   
												   0x0   0x0   0x0   
												   0x0   0x0   0x0   
												   0x0   0x0   0x0   
												   0x0   0x0   0x0   
												   0x0   0x0   0x0   
												   0x0   0x0   0x0   
												   0x0   0x0   0x0   
												   0x0   0x0   0x0   
												   0x0   0x0   0x0   
												   0x0   0x0   0x0   
												   0x0   0x0   0x0   
												   0x0   0x0   0x0   
												   0x0   0x0   0x0   
												   0x0   0x0   0x0   
												   0x0   0x0   0x0   
												   0x0   0x0   0x0   
												   0x0   0x0   0x0   
												   0x0   0x0   0x0   
												   0x0   0x0   0x0   
												   0x0   0x0   0x0   
												   0x0   0x0   0x0   
												   0x0   0x0   0x0   
												   0x0   0x0   0x0   
												   0x0   0x0   0x0   
												   0x0   0x0   0x0   
												   0x0   0x0   0x0   
												   0x0   0x0   0x0   
												   0x0   0x0   0x0   
												   0x0   0x0   0x0   
												   0x0   0x0   0x0   
												   0x0   0x0   0x0   
												   0x0   0x0   0x0   
												   0x0   0x0   0x0   
												   0x0   0x0   0x0   
												   0x0   0x0   0x0   
												   0x0   0x0   0x0   
												   0x0   0x0   0x0   
												   0x0   0x0   0x0   
												   0x0   0x0   0x0   
												   0x0   0x0   0x0   
												   0x0   0x0   0x0   
												   0x0   0x0   0x0   
												   0x0   0x0   0x0   
												   0x0   0x0   0x0   
												   0x0   0x0   0x0   
												   0x0   0x0   0x0   
												   0x0   0x0   0x0   
												   0x0   0x0   0x0   
												   0x0   0x0   0x0 >;
		};
		macinfo{
			compatible="alitech,macinfo";
			phyaddr0 = /bits/ 8 <0xde 0xad 0xbe 0xef 0x1b 0x01 0x61 0x61>;
			phyaddr1 = /bits/ 8 <0x12 0x22 0x33 0x44 0x55 0x66 0x65 0x33>;
			phyaddr2 = /bits/ 8 <0x22 0x32 0x43 0x54 0x65 0x76 0x85 0x93>;
			phyaddr3 = /bits/ 8 <0x02 0x12 0x23 0x34 0x45 0x56 0x65 0x73>;
		};
		media_info{
			compatible="alitech,media_info";
			play_enable = <0x1>;
			start_cmd		= <0x0>;
			finish_cmd	= <0x0>;
			jpeg_show_status	= <0x0>;	
			mpeg2_show_status	= <0x0>;
			mkv_show_status	= <0x0>;
			smart_output_enable	= <0x0>;
		};
		gma_info{
				compatible="alitech,gma_info";
				gma_enable = <0x0>;
				gma_layer_id = <0x0>;
				format = <0x0>;
				x = <0x0>;
				y = <0x0>;
				w = <0x0>;
				h = <0x0>;
				gma_buffer = <0x0>;
				gma_pitch = <0x0>;
				pallett = <
									0x0 0x0 0x0 0x0 0x0 0x0 0x0 0x0 0x0 0x0 0x0 0x0 0x0 0x0 0x0 0x0 0x0 0x0 0x0 0x0
									0x0 0x0 0x0 0x0 0x0 0x0 0x0 0x0 0x0 0x0 0x0 0x0 0x0 0x0 0x0 0x0 0x0 0x0 0x0 0x0
									0x0 0x0 0x0 0x0 0x0 0x0 0x0 0x0 0x0 0x0 0x0 0x0 0x0 0x0 0x0 0x0 0x0 0x0 0x0 0x0
									0x0 0x0 0x0 0x0 0x0 0x0 0x0 0x0 0x0 0x0 0x0 0x0 0x0 0x0 0x0 0x0 0x0 0x0 0x0 0x0
									0x0 0x0 0x0 0x0 0x0 0x0 0x0 0x0 0x0 0x0 0x0 0x0 0x0 0x0 0x0 0x0 0x0 0x0 0x0 0x0
									0x0 0x0 0x0 0x0 0x0 0x0 0x0 0x0 0x0 0x0 0x0 0x0 0x0 0x0 0x0 0x0 0x0 0x0 0x0 0x0
									0x0 0x0 0x0 0x0 0x0 0x0 0x0 0x0 0x0 0x0 0x0 0x0 0x0 0x0 0x0 0x0 0x0 0x0 0x0 0x0
									0x0 0x0 0x0 0x0 0x0 0x0 0x0 0x0 0x0 0x0 0x0 0x0 0x0 0x0 0x0 0x0 0x0 0x0 0x0 0x0
									0x0 0x0 0x0 0x0 0x0 0x0 0x0 0x0 0x0 0x0 0x0 0x0 0x0 0x0 0x0 0x0 0x0 0x0 0x0 0x0
									0x0 0x0 0x0 0x0 0x0 0x0 0x0 0x0 0x0 0x0 0x0 0x0 0x0 0x0 0x0 0x0 0x0 0x0 0x0 0x0
									0x0 0x0 0x0 0x0 0x0 0x0 0x0 0x0 0x0 0x0 0x0 0x0 0x0 0x0 0x0 0x0 0x0 0x0 0x0 0x0
									0x0 0x0 0x0 0x0 0x0 0x0 0x0 0x0 0x0 0x0 0x0 0x0 0x0 0x0 0x0 0x0 0x0 0x0 0x0 0x0
									0x0 0x0 0x0 0x0 0x0 0x0 0x0 0x0 0x0 0x0 0x0 0x0 0x0 0x0 0x0 0x0 >;
				full_screen = <0x0>;
		};
		heart_beat{
				compatible="alitech,heart_beat";
				live_flag = <0x0>;
				live_tick = <0x0>;
		};
};
